# STM32N647xx register map
File version: 1.0
Registers are 32-bit, read-write, reset 0x0 unless marked. A register's access mark holds for its fields unless they carry their own. Offsets are from the block's base; [hi:lo] are bit positions; {n}, {i} and the like mark numbered series.

## WWDG — Window Watchdog
Base 0x40002C00
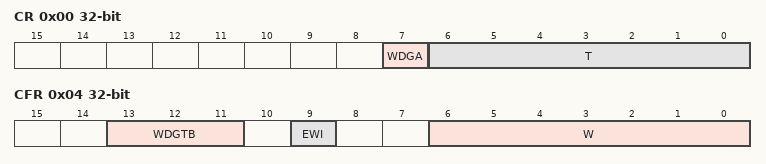
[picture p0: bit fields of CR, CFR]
0x00 CR — WWDG Control register
  [7] WDGA — Activation bit
  [6:0] T — T[6:0] bits (7-Bit counter (MSB to LSB))
0x04 CFR — WWDG Configuration register
  [13:11] WDGTB — WDGTB[2:0] bits (Timer Base)
    0=PRESCALER_1 (WWDG counter clock = (PCLK1/4096)/1); 1=PRESCALER_2 (WWDG counter clock = (PCLK1/4096)/2); 2=PRESCALER_4 (WWDG counter clock = (PCLK1/4096)/4); 3=PRESCALER_8 (WWDG counter clock = (PCLK1/4096)/8); 4=PRESCALER_16 (WWDG counter clock = (PCLK1/4096)/16); 5=PRESCALER_32 (WWDG counter clock = (PCLK1/4096)/32); 6=PRESCALER_64 (WWDG counter clock = (PCLK1/4096)/64); 7=PRESCALER_128 (WWDG counter clock = (PCLK1/4096)/128)
  [9] EWI — Early Wakeup Interrupt
  [6:0] W — W[6:0] bits (7-bit window value)
0x08 SR — WWDG Status register
  [0] EWIF — Early Wakeup Interrupt Flag

## SPDIFRX — SPDIF-RX Interface
Base 0x40004000
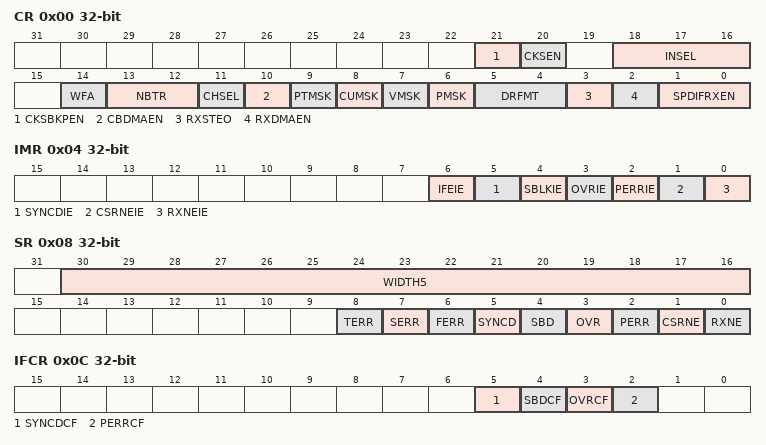
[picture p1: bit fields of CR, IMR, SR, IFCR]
0x00 CR — Control register
  [21] CKSBKPEN — Backup Symbol Clock Enable
  [20] CKSEN — Symbol Clock Enable
  [18:16] INSEL — SPDIF input selection
  [14] WFA — Wait For Activity
  [13:12] NBTR — Maximum allowed re-tries during synchronization phase
  [11] CHSEL — Channel Selection
  [10] CBDMAEN — Control Buffer DMA ENable for control flow
  [9] PTMSK — Mask of Preamble Type bits
  [8] CUMSK — Mask of channel status and user bits
  [7] VMSK — Mask of Validity bit
  [6] PMSK — Mask Parity error bit
  [5:4] DRFMT — RX Data format
  [3] RXSTEO — Stereo Mode
  [2] RXDMAEN — Receiver DMA Enable for data flow
  [1:0] SPDIFRXEN — Peripheral Block Enable
0x04 IMR — Interrupt mask register
  [6] IFEIE — Serial Interface Error Interrupt Enable
  [5] SYNCDIE — Synchronization Done
  [4] SBLKIE — Synchronization Block Detected Interrupt Enable
  [3] OVRIE — Overrun error Interrupt Enable
  [2] PERRIE — Parity error interrupt enable
  [1] CSRNEIE — Control Buffer Ready Interrupt Enable
  [0] RXNEIE — RXNE interrupt enable
0x08 SR — Status register
  [30:16] WIDTH5 — Duration of 5 symbols counted with spdif_clk
  [8] TERR — Time-out error
  [7] SERR — Synchronization error
  [6] FERR — Framing error
  [5] SYNCD — Synchronization Done
  [4] SBD — Synchronization Block Detected
  [3] OVR — Overrun error
  [2] PERR — Parity error
  [1] CSRNE — The Control Buffer register is not empty
  [0] RXNE — Read data register not empty
0x0C IFCR — Interrupt Flag Clear register
  [5] SYNCDCF — Clears the Synchronization Done flag
  [4] SBDCF — Clears the Synchronization Block Detected flag
  [3] OVRCF — Clears the Overrun error flag
  [2] PERRCF — Clears the Parity error flag
0x10 DR — Data input register
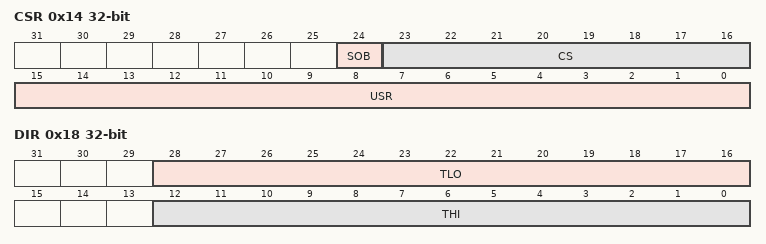
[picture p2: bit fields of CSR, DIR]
0x14 CSR — Channel Status register
  [24] SOB — Start Of Block
  [23:16] CS — Channel A status information
  [15:0] USR — User data information
0x18 DIR — Debug Information register
  [28:16] TLO — Threshold HIGH
  [12:0] THI — Threshold LOW

## MDIOS
Base 0x40009400
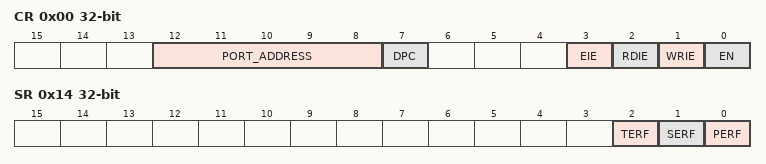
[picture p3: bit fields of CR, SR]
0x00 CR
  [12:8] PORT_ADDRESS — MDIOS slave port address mask
  [7] DPC — MDIOS slave disable preamble check
  [3] EIE — MDIOS slave register error interrupt enable
  [2] RDIE — MDIOS slave register read interrupt enable
  [1] WRIE — MDIOS slave register write interrupt enable
  [0] EN — MDIOS slave peripheral enable
0x04 WRFR
0x08 CWRFR
0x0C RDFR
0x10 CRDFR
0x14 SR
  [2] TERF — MDIOS slave preamble error flag
  [1] SERF — MDIOS slave start error flag
  [0] PERF — MDIOS slave turnaround error flag
0x18 CLRFR
{0x100+4i} DINR{i} (i=0..31)
{0x180+4i} DOUTR{i} (i=0..31)

## FDCAN_CCU — FD Controller Area Network
Base 0x4000A800
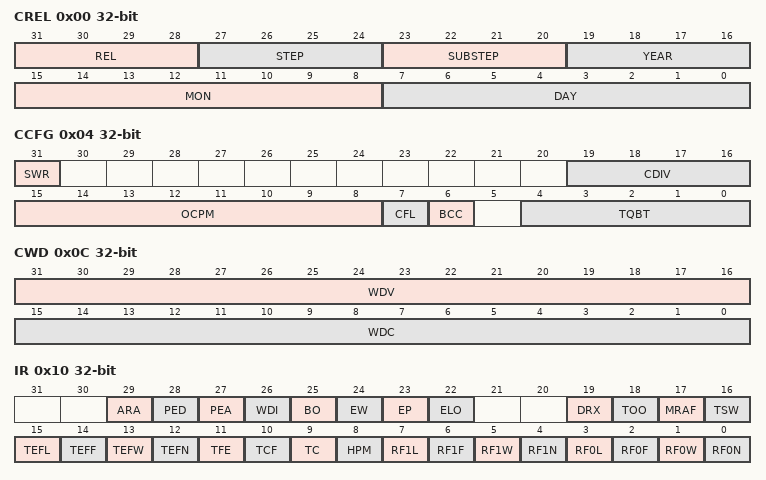
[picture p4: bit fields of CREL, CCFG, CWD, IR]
0x00 CREL — Clock Calibration Unit Core Release register
  [31:28] REL — Core release
  [27:24] STEP — Step of Core release
  [23:20] SUBSTEP — Sub-step of Core release
  [19:16] YEAR — Timestamp Year
  [15:8] MON — Timestamp Month
  [7:0] DAY — Timestamp Day
0x04 CCFG — Calibration Configuration register
  [31] SWR — Software Reset
  [19:16] CDIV — Clock Divider
  [15:8] OCPM — Oscillator Clock Periods Minimum
  [7] CFL — Calibration Field Length
  [6] BCC — Bypass Clock Calibration
  [4:0] TQBT — Time Quanta per Bit Time
0x08 CSTAT — Calibration Status register
0x0C CWD — Calibration Watchdog register
  [31:16] WDV — Watchdog Value
  [15:0] WDC — Watchdog Configuration
0x10 IR — CCU Interrupt register
  [29] ARA — Access to Reserved Address
  [28] PED — Protocol Error in Data Phase
  [27] PEA — Protocol Error in Arbitration Phase
  [26] WDI — Watchdog Interrupt
  [25] BO — Bus_Off Status
  [24] EW — Warning Status
  [23] EP — Error Passive
  [22] ELO — Error Logging Overflow
  [19] DRX — Message stored to Dedicated Rx Buffer
  [18] TOO — Timeout Occurred
  [17] MRAF — Message RAM Access Failure
  [16] TSW — Timestamp Wraparound
  [15] TEFL — Tx Event FIFO Element Lost
  [14] TEFF — Tx Event FIFO Full
  [13] TEFW — Tx Event FIFO Watermark Reached
  [12] TEFN — Tx Event FIFO New Entry
  [11] TFE — Tx FIFO Empty
  [10] TCF — Transmission Cancellation Finished
  [9] TC — Transmission Completed
  [8] HPM — High Priority Message
  [7] RF1L — Rx FIFO 1 Message Lost
  [6] RF1F — Rx FIFO 1 Full
  [5] RF1W — Rx FIFO 1 Watermark Reached
  [4] RF1N — Rx FIFO 1 New Message
  [3] RF0L — Rx FIFO 0 Message Lost
  [2] RF0F — Rx FIFO 0 Full
  [1] RF0W — Rx FIFO 0 Watermark Reached
  [0] RF0N — Rx FIFO 0 New Message
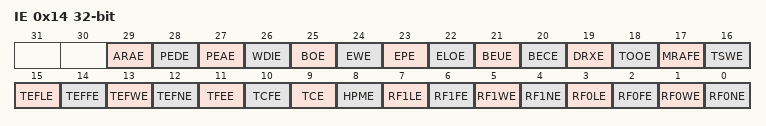
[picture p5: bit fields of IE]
0x14 IE — CCU Interrupt Enable register
  [29] ARAE — Access to Reserved Address Enable
  [28] PEDE — Protocol Error in Data Phase Enable
  [27] PEAE — Protocol Error in Arbitration Phase Enable
  [26] WDIE — Watchdog Interrupt Enable
  [25] BOE — Bus_Off Status Enable
  [24] EWE — Warning Status Enable
  [23] EPE — Error Passive Enable
  [22] ELOE — Error Logging Overflow Enable
  [21] BEUE — Bit Error Uncorrected Interrupt Enable
  [20] BECE — Bit Error Corrected Interrupt Enable
  [19] DRXE — Message stored to Dedicated Rx Buffer Enable
  [18] TOOE — Timeout Occurred Enable
  [17] MRAFE — Message RAM Access Failure Enable
  [16] TSWE — Timestamp Wraparound Enable
  [15] TEFLE — Tx Event FIFO Element Lost Enable
  [14] TEFFE — Tx Event FIFO Full Enable
  [13] TEFWE — Tx Event FIFO Watermark Reached Enable
  [12] TEFNE — Tx Event FIFO New Entry Enable
  [11] TFEE — Tx FIFO Empty Enable
  [10] TCFE — Transmission Cancellation Finished Enable
  [9] TCE — Transmission Completed Enable
  [8] HPME — High Priority Message Enable
  [7] RF1LE — Rx FIFO 1 Message Lost Enable
  [6] RF1FE — Rx FIFO 1 Full Enable
  [5] RF1WE — Rx FIFO 1 Watermark Reached Enable
  [4] RF1NE — Rx FIFO 1 New Message Enable
  [3] RF0LE — Rx FIFO 0 Message Lost Enable
  [2] RF0FE — Rx FIFO 0 Full Enable
  [1] RF0WE — Rx FIFO 0 Watermark Reached Enable
  [0] RF0NE — Rx FIFO 0 New Message Enable
